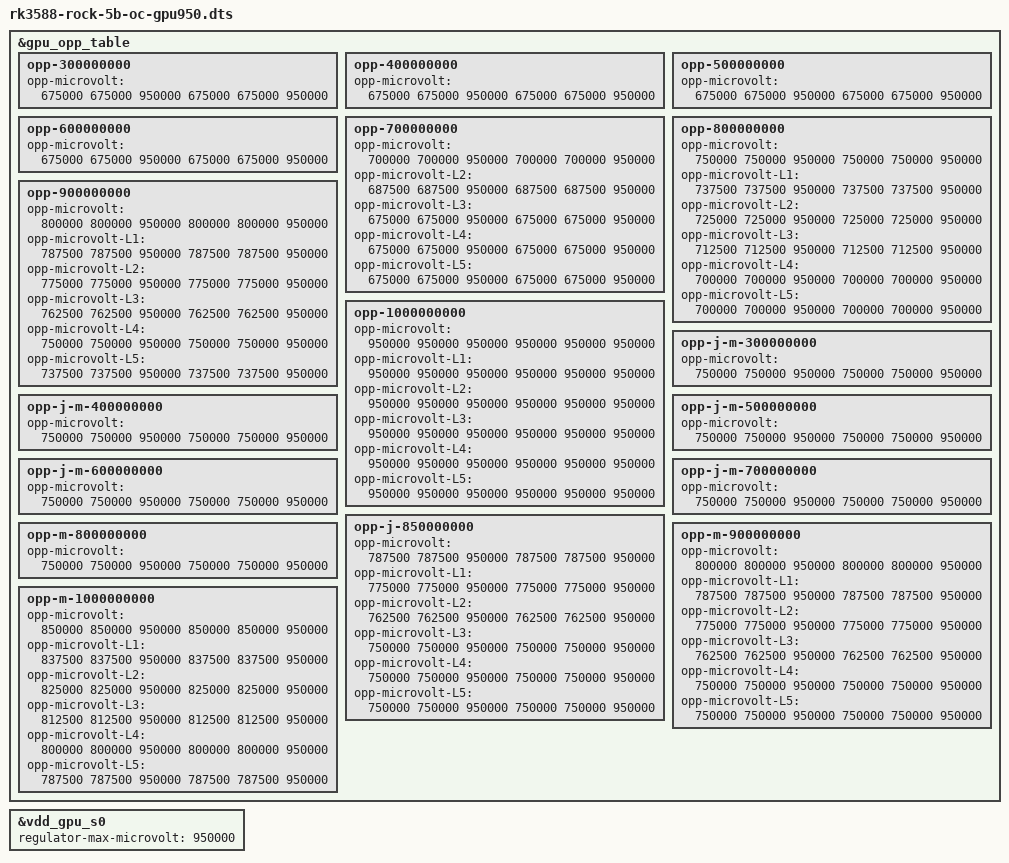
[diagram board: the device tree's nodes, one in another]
/dts-v1/;
/plugin/;

// RK3588 (ROCK 5B, vendor kernel) overclock: GPU 1 GHz OPP 950 mV.
// PVTPLL sets the real clocks from the voltage. Tested stable on one ROCK 5B (GPU PVTM level 5, A76 levels 6/7,
// A55 level 6) with glmark2 / all-core self-checking stress. Other chips (bins) may differ: if it does not boot,
// remove the FDTOVERLAYS line from extlinux/extlinux.conf on the boot partition from a PC.
// Generated by gen_oc.py from the kernel's rk3588-rock-5b.dtb; every OPP's max is raised so that the core and
// memory supplies (one regulator) can always step down.

&gpu_opp_table {
	opp-300000000 {
		opp-microvolt = <675000 675000 950000 675000 675000 950000>;
	};
	opp-400000000 {
		opp-microvolt = <675000 675000 950000 675000 675000 950000>;
	};
	opp-500000000 {
		opp-microvolt = <675000 675000 950000 675000 675000 950000>;
	};
	opp-600000000 {
		opp-microvolt = <675000 675000 950000 675000 675000 950000>;
	};
	opp-700000000 {
		opp-microvolt = <700000 700000 950000 700000 700000 950000>;
		opp-microvolt-L2 = <687500 687500 950000 687500 687500 950000>;
		opp-microvolt-L3 = <675000 675000 950000 675000 675000 950000>;
		opp-microvolt-L4 = <675000 675000 950000 675000 675000 950000>;
		opp-microvolt-L5 = <675000 675000 950000 675000 675000 950000>;
	};
	opp-800000000 {
		opp-microvolt = <750000 750000 950000 750000 750000 950000>;
		opp-microvolt-L1 = <737500 737500 950000 737500 737500 950000>;
		opp-microvolt-L2 = <725000 725000 950000 725000 725000 950000>;
		opp-microvolt-L3 = <712500 712500 950000 712500 712500 950000>;
		opp-microvolt-L4 = <700000 700000 950000 700000 700000 950000>;
		opp-microvolt-L5 = <700000 700000 950000 700000 700000 950000>;
	};
	opp-900000000 {
		opp-microvolt = <800000 800000 950000 800000 800000 950000>;
		opp-microvolt-L1 = <787500 787500 950000 787500 787500 950000>;
		opp-microvolt-L2 = <775000 775000 950000 775000 775000 950000>;
		opp-microvolt-L3 = <762500 762500 950000 762500 762500 950000>;
		opp-microvolt-L4 = <750000 750000 950000 750000 750000 950000>;
		opp-microvolt-L5 = <737500 737500 950000 737500 737500 950000>;
	};
	opp-1000000000 {
		opp-microvolt = <950000 950000 950000 950000 950000 950000>;
		opp-microvolt-L1 = <950000 950000 950000 950000 950000 950000>;
		opp-microvolt-L2 = <950000 950000 950000 950000 950000 950000>;
		opp-microvolt-L3 = <950000 950000 950000 950000 950000 950000>;
		opp-microvolt-L4 = <950000 950000 950000 950000 950000 950000>;
		opp-microvolt-L5 = <950000 950000 950000 950000 950000 950000>;
	};
	opp-j-m-300000000 {
		opp-microvolt = <750000 750000 950000 750000 750000 950000>;
	};
	opp-j-m-400000000 {
		opp-microvolt = <750000 750000 950000 750000 750000 950000>;
	};
	opp-j-m-500000000 {
		opp-microvolt = <750000 750000 950000 750000 750000 950000>;
	};
	opp-j-m-600000000 {
		opp-microvolt = <750000 750000 950000 750000 750000 950000>;
	};
	opp-j-m-700000000 {
		opp-microvolt = <750000 750000 950000 750000 750000 950000>;
	};
	opp-j-850000000 {
		opp-microvolt = <787500 787500 950000 787500 787500 950000>;
		opp-microvolt-L1 = <775000 775000 950000 775000 775000 950000>;
		opp-microvolt-L2 = <762500 762500 950000 762500 762500 950000>;
		opp-microvolt-L3 = <750000 750000 950000 750000 750000 950000>;
		opp-microvolt-L4 = <750000 750000 950000 750000 750000 950000>;
		opp-microvolt-L5 = <750000 750000 950000 750000 750000 950000>;
	};
	opp-m-800000000 {
		opp-microvolt = <750000 750000 950000 750000 750000 950000>;
	};
	opp-m-900000000 {
		opp-microvolt = <800000 800000 950000 800000 800000 950000>;
		opp-microvolt-L1 = <787500 787500 950000 787500 787500 950000>;
		opp-microvolt-L2 = <775000 775000 950000 775000 775000 950000>;
		opp-microvolt-L3 = <762500 762500 950000 762500 762500 950000>;
		opp-microvolt-L4 = <750000 750000 950000 750000 750000 950000>;
		opp-microvolt-L5 = <750000 750000 950000 750000 750000 950000>;
	};
	opp-m-1000000000 {
		opp-microvolt = <850000 850000 950000 850000 850000 950000>;
		opp-microvolt-L1 = <837500 837500 950000 837500 837500 950000>;
		opp-microvolt-L2 = <825000 825000 950000 825000 825000 950000>;
		opp-microvolt-L3 = <812500 812500 950000 812500 812500 950000>;
		opp-microvolt-L4 = <800000 800000 950000 800000 800000 950000>;
		opp-microvolt-L5 = <787500 787500 950000 787500 787500 950000>;
	};
};
&vdd_gpu_s0 { regulator-max-microvolt = <950000>; };
